# RP2350 register map
Vendor: Raspberry Pi; Series: RP; File version: 0.1
CPU: CM33 r1p0, little endian, MPU, FPU, DSP, VTOR, 4 interrupt priority bits, 52 interrupts, 8 SAU regions
Registers are 32-bit, read-write, reset 0x0 unless marked. A register's access mark holds for its fields unless they carry their own. Offsets are from the block's base; [hi:lo] are bit positions; {n}, {i} and the like mark numbered series; 'fields as' and 'values as' point back to an identical list.

## RESETS
Base 0x40020000
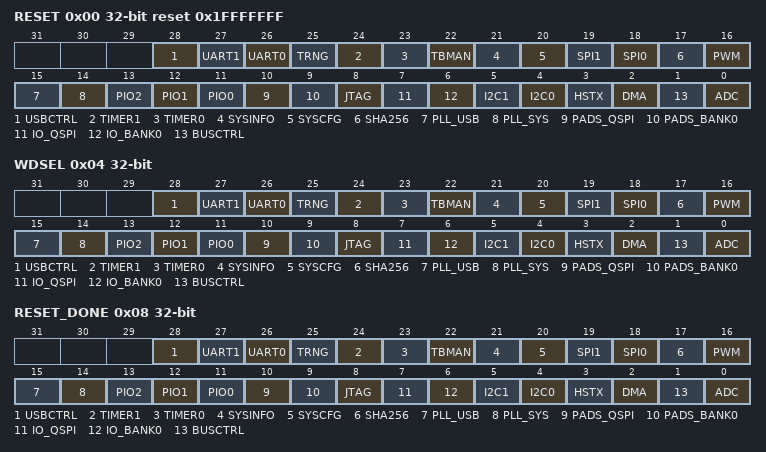
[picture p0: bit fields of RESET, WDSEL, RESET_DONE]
0x00 RESET reset 0x1FFFFFFF
  [28] USBCTRL, [27] UART1, [26] UART0, [25] TRNG, [24] TIMER1, [23] TIMER0, [22] TBMAN, [21] SYSINFO, [20] SYSCFG, [19] SPI1, [18] SPI0, [17] SHA256, [16] PWM, [15] PLL_USB, [14] PLL_SYS, [13] PIO2, [12] PIO1, [11] PIO0, [10] PADS_QSPI, [9] PADS_BANK0, [8] JTAG, [7] IO_QSPI, [6] IO_BANK0, [5] I2C1, [4] I2C0, [3] HSTX, [2] DMA, [1] BUSCTRL, [0] ADC
0x04 WDSEL
  fields as RESET
0x08 RESET_DONE
  [28] USBCTRL ro, [27] UART1 ro, [26] UART0 ro, [25] TRNG ro, [24] TIMER1 ro, [23] TIMER0 ro, [22] TBMAN ro, [21] SYSINFO ro, [20] SYSCFG ro, [19] SPI1 ro, [18] SPI0 ro, [17] SHA256 ro, [16] PWM ro, [15] PLL_USB ro, [14] PLL_SYS ro, [13] PIO2 ro, [12] PIO1 ro, [11] PIO0 ro, [10] PADS_QSPI ro, [9] PADS_BANK0 ro, [8] JTAG ro, [7] IO_QSPI ro, [6] IO_BANK0 ro, [5] I2C1 ro, [4] I2C0 ro, [3] HSTX ro, [2] DMA ro, [1] BUSCTRL ro, [0] ADC ro

## PSM
Base 0x40018000
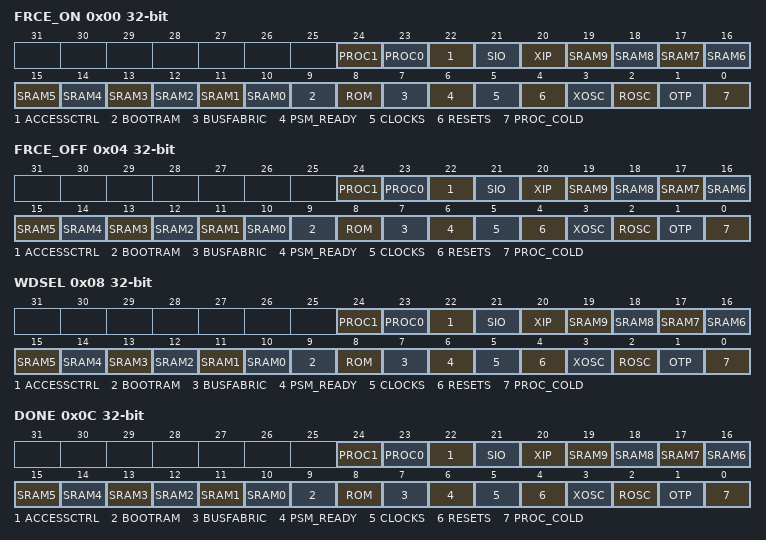
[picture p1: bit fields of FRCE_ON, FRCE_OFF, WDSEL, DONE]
0x00 FRCE_ON — Force block out of reset (i.e. power it on)
  [24] PROC1, [23] PROC0, [22] ACCESSCTRL, [21] SIO, [20] XIP, [n+10] SRAM{n} (n=0..9), [9] BOOTRAM, [8] ROM, [7] BUSFABRIC, [6] PSM_READY, [5] CLOCKS, [4] RESETS, [3] XOSC, [2] ROSC, [1] OTP, [0] PROC_COLD
0x04 FRCE_OFF — Force into reset (i.e. power it off)
  fields as FRCE_ON
0x08 WDSEL — Set to 1 if the watchdog should reset this
  fields as FRCE_ON
0x0C DONE — Is the subsystem ready?
  [24] PROC1 ro, [23] PROC0 ro, [22] ACCESSCTRL ro, [21] SIO ro, [20] XIP ro, [n+10] SRAM{n} ro (n=0..9), [9] BOOTRAM ro, [8] ROM ro, [7] BUSFABRIC ro, [6] PSM_READY ro, [5] CLOCKS ro, [4] RESETS ro, [3] XOSC ro, [2] ROSC ro, [1] OTP ro, [0] PROC_COLD ro

## TICKS
Base 0x40108000
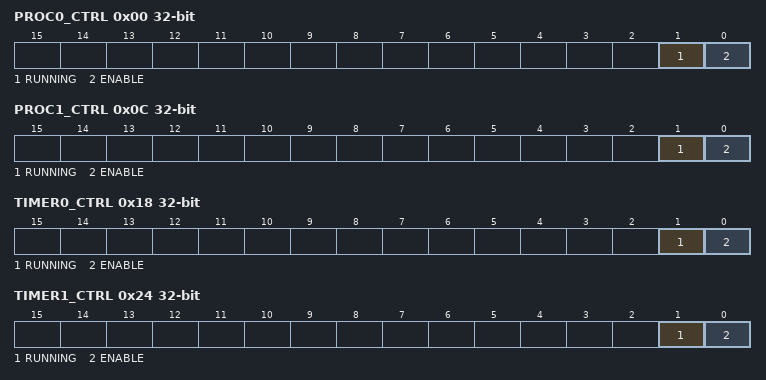
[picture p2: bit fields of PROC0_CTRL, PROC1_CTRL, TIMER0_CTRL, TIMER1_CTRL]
0x00 PROC0_CTRL — Controls the tick generator
  [1] RUNNING ro — Is the tick generator running?
  [0] ENABLE — start / stop tick generation
0x04 PROC0_CYCLES
  [8:0] PROC0_CYCLES — Total number of clk_tick cycles before the next tick.
0x08 PROC0_COUNT reset not defined
  [8:0] PROC0_COUNT ro — Count down timer: the remaining number clk_tick cycles before the next tick is generated.
0x0C PROC1_CTRL — Controls the tick generator
  fields as PROC0_CTRL
0x10 PROC1_CYCLES
  [8:0] PROC1_CYCLES — Total number of clk_tick cycles before the next tick.
0x14 PROC1_COUNT reset not defined
  [8:0] PROC1_COUNT ro — Count down timer: the remaining number clk_tick cycles before the next tick is generated.
0x18 TIMER0_CTRL — Controls the tick generator
  fields as PROC0_CTRL
0x1C TIMER0_CYCLES
  [8:0] TIMER0_CYCLES — Total number of clk_tick cycles before the next tick.
0x20 TIMER0_COUNT reset not defined
  [8:0] TIMER0_COUNT ro — Count down timer: the remaining number clk_tick cycles before the next tick is generated.
0x24 TIMER1_CTRL — Controls the tick generator
  fields as PROC0_CTRL
0x28 TIMER1_CYCLES
  [8:0] TIMER1_CYCLES — Total number of clk_tick cycles before the next tick.
0x2C TIMER1_COUNT reset not defined
  [8:0] TIMER1_COUNT ro — Count down timer: the remaining number clk_tick cycles before the next tick is generated.
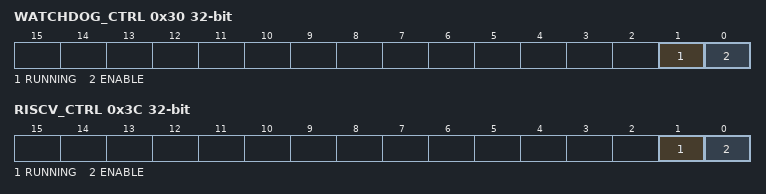
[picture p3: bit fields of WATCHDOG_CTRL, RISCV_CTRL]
0x30 WATCHDOG_CTRL — Controls the tick generator
  fields as PROC0_CTRL
0x34 WATCHDOG_CYCLES
  [8:0] WATCHDOG_CYCLES — Total number of clk_tick cycles before the next tick.
0x38 WATCHDOG_COUNT reset not defined
  [8:0] WATCHDOG_COUNT ro — Count down timer: the remaining number clk_tick cycles before the next tick is generated.
0x3C RISCV_CTRL — Controls the tick generator
  fields as PROC0_CTRL
0x40 RISCV_CYCLES
  [8:0] RISCV_CYCLES — Total number of clk_tick cycles before the next tick.
0x44 RISCV_COUNT reset not defined
  [8:0] RISCV_COUNT ro — Count down timer: the remaining number clk_tick cycles before the next tick is generated.

## Notices in the file
Copyright (c) 2024 Raspberry Pi Ltd.
SPDX-License-Identifier: BSD-3-Clause
